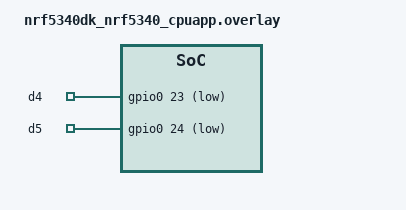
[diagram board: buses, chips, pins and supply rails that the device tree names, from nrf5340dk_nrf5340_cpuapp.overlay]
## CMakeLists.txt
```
# SPDX-License-Identifier: Apache-2.0
cmake_minimum_required(VERSION 3.20.0)

set(ZEPHYR_EXTRA_MODULES "${CMAKE_SOURCE_DIR}/../modules/button")
find_package(Zephyr REQUIRED HINTS $ENV{ZEPHYR_BASE})
project(button)

target_sources(app PRIVATE src/main.c)
```

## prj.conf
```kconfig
CONFIG_SIMPLE_BUTTON=y
CONFIG_LOG=y
```

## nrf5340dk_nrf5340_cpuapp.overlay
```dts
/ {
    aliases {
        my-button-1 = &cbutton_1;
        my-button-2 = &cbutton_2;
    };

    simple-button {
        cbutton_1: custom_button_1 {
            compatible = "simple,button";
            pin = <&d4>;
        };

        cbutton_2: custom_button_2 {
            compatible = "simple,button";
            pin = <&d5>;
        };
    };

    gpio-keys {
        compatible = "gpio-keys";
        debounce-interval-ms = <50>;
        polling-mode;

		d4: gpio4 {
			gpios = <&gpio0 23 (GPIO_PULL_UP | GPIO_ACTIVE_LOW)>;
		};

		d5: gpio5 {
			gpios = <&gpio0 24 (GPIO_PULL_UP | GPIO_ACTIVE_LOW)>;
		};
    };
};
```

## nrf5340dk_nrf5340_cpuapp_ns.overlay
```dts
/ {
	aliases {
		my-button-1 = &button1;
		my-button-2 = &button2;
	};

	simple_button: button {
		button_1: simple_button_1 {
			compatible = "simple,button";
			pin = <&d4>;
		};

		button_2: simple_button_2 {
			compatible = "custom,button";
			pin = <&d5>;
		};
	};

	gpio_keys {
		compatible = "gpio-keys";
		debounce-interval-ms = <50>;
		polling-mode;

		d4: gpio4 {
			gpios = <&gpio0 4 (GPIO_PULL_UP | GPIO_ACTIVE_LOW)>;
		};

		d5: gpio5 {
			gpios = <&gpio0 5 (GPIO_PULL_UP | GPIO_ACTIVE_LOW)>;
		};


	};
};
```

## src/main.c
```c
#include "simple_button.h"

#include <stdint.h>
#include <stdio.h>
#include <zephyr/kernel.h>

static const struct device *btn_dev = DEVICE_DT_GET(DT_ALIAS(my_button_1));
static const struct device *btn_dev2 = DEVICE_DT_GET(DT_ALIAS(my_button_2));

int main(void)
{
    if (!device_is_ready(btn_dev))
    {
        printf("Button device not ready\n");
        return -1;
    }

    if (!device_is_ready(btn_dev2))
    {
        printf("Button device 2 not ready\n");
        return -1;
    }

    const struct button_api *btn_api = (const struct button_api *)btn_dev->api;

    uint8_t val = 0;
    uint8_t val2 = 0;

    for (;;)
    {
        int ret = btn_api->get(btn_dev, &val);
        if (ret < 0)
            printf("not able to do a get val\n");

        ret = btn_api->get(btn_dev2, &val2);
        if (ret < 0)
            printf("not able to do a get val\n");

        printf("%u, %u\n", val, val2);

        k_msleep(100);
    }

    return 0;
}
```
